VERSION ""

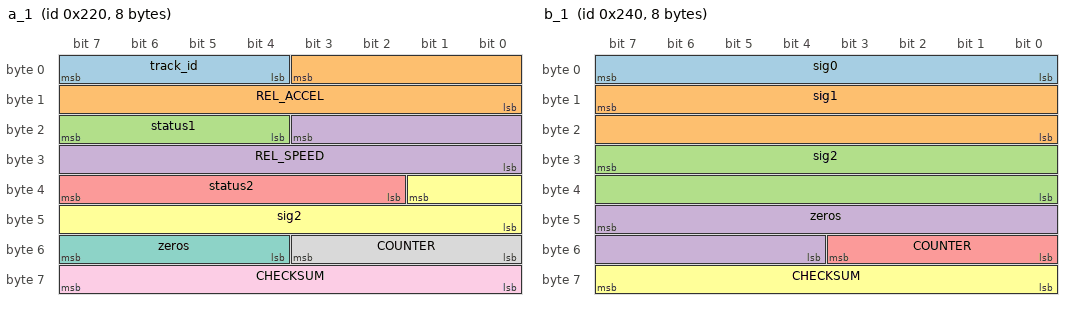
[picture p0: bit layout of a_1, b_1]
BO_ 544 a_1: 8 XXX
 SG_ track_id : 7|4@0+ (1,0) [0|15] "" XXX
 SG_ REL_ACCEL : 3|12@0+ (1,0) [0|31] "" XXX
 SG_ status1 : 23|4@0+ (1,0) [0|15] "" XXX
 SG_ REL_SPEED : 19|12@0+ (1,0) [0|65535] "" XXX
 SG_ status2 : 39|6@0+ (1,0) [0|15] "" XXX
 SG_ sig2 : 33|10@0+ (1,0) [0|255] "" XXX
 SG_ zeros : 55|4@0+ (1,0) [0|15] "" XXX
 SG_ COUNTER : 51|4@0+ (1,0) [0|15] "" XXX
 SG_ CHECKSUM : 63|8@0+ (1,0) [0|255] "" XXX

BO_ 576 b_1: 8 XXX
 SG_ sig0 : 7|8@0+ (1,0) [0|255] "" XXX
 SG_ sig1 : 15|16@0+ (1,0) [0|65535] "" XXX
 SG_ sig2 : 31|16@0+ (1,0) [0|255] "" XXX
 SG_ zeros : 47|12@0+ (1,0) [0|255] "" XXX
 SG_ COUNTER : 51|4@0+ (1,0) [0|15] "" XXX
 SG_ CHECKSUM : 63|8@0+ (1,0) [0|255] "" XXX

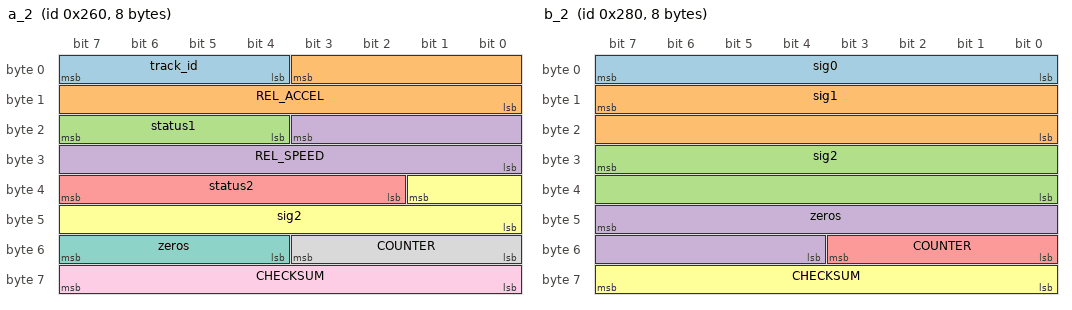
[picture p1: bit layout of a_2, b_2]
BO_ 608 a_2: 8 XXX
 SG_ track_id : 7|4@0+ (1,0) [0|15] "" XXX
 SG_ REL_ACCEL : 3|12@0+ (1,0) [0|31] "" XXX
 SG_ status1 : 23|4@0+ (1,0) [0|15] "" XXX
 SG_ REL_SPEED : 19|12@0+ (1,0) [0|65535] "" XXX
 SG_ status2 : 39|6@0+ (1,0) [0|15] "" XXX
 SG_ sig2 : 33|10@0+ (1,0) [0|255] "" XXX
 SG_ zeros : 55|4@0+ (1,0) [0|15] "" XXX
 SG_ COUNTER : 51|4@0+ (1,0) [0|15] "" XXX
 SG_ CHECKSUM : 63|8@0+ (1,0) [0|255] "" XXX

BO_ 640 b_2: 8 XXX
 SG_ sig0 : 7|8@0+ (1,0) [0|255] "" XXX
 SG_ sig1 : 15|16@0+ (1,0) [0|65535] "" XXX
 SG_ sig2 : 31|16@0+ (1,0) [0|255] "" XXX
 SG_ zeros : 47|12@0+ (1,0) [0|255] "" XXX
 SG_ COUNTER : 51|4@0+ (1,0) [0|15] "" XXX
 SG_ CHECKSUM : 63|8@0+ (1,0) [0|255] "" XXX

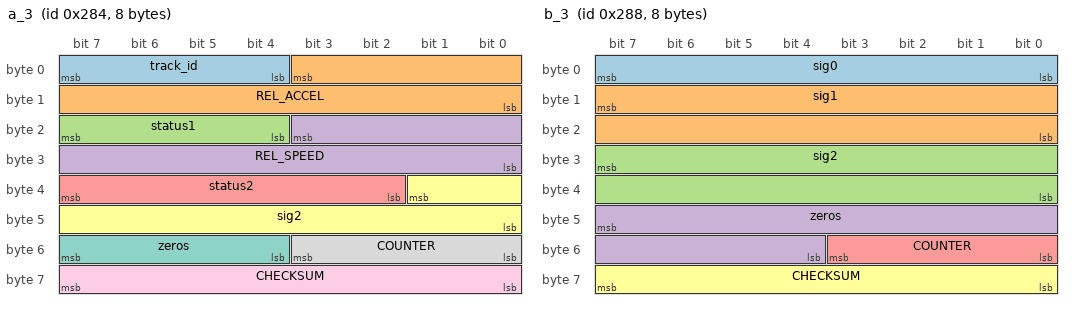
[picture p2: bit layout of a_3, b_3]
BO_ 644 a_3: 8 XXX
 SG_ track_id : 7|4@0+ (1,0) [0|15] "" XXX
 SG_ REL_ACCEL : 3|12@0+ (1,0) [0|31] "" XXX
 SG_ status1 : 23|4@0+ (1,0) [0|15] "" XXX
 SG_ REL_SPEED : 19|12@0+ (1,0) [0|65535] "" XXX
 SG_ status2 : 39|6@0+ (1,0) [0|15] "" XXX
 SG_ sig2 : 33|10@0+ (1,0) [0|255] "" XXX
 SG_ zeros : 55|4@0+ (1,0) [0|15] "" XXX
 SG_ COUNTER : 51|4@0+ (1,0) [0|15] "" XXX
 SG_ CHECKSUM : 63|8@0+ (1,0) [0|255] "" XXX

BO_ 648 b_3: 8 XXX
 SG_ sig0 : 7|8@0+ (1,0) [0|255] "" XXX
 SG_ sig1 : 15|16@0+ (1,0) [0|65535] "" XXX
 SG_ sig2 : 31|16@0+ (1,0) [0|255] "" XXX
 SG_ zeros : 47|12@0+ (1,0) [0|255] "" XXX
 SG_ COUNTER : 51|4@0+ (1,0) [0|15] "" XXX
 SG_ CHECKSUM : 63|8@0+ (1,0) [0|255] "" XXX

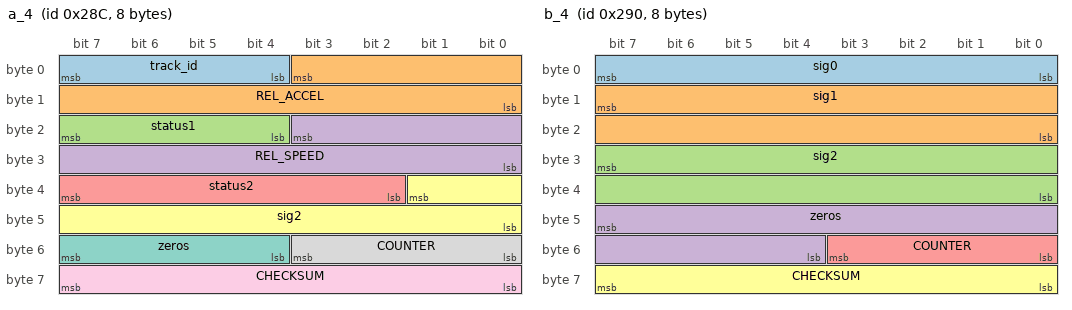
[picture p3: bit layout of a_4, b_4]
BO_ 652 a_4: 8 XXX
 SG_ track_id : 7|4@0+ (1,0) [0|15] "" XXX
 SG_ REL_ACCEL : 3|12@0+ (1,0) [0|31] "" XXX
 SG_ status1 : 23|4@0+ (1,0) [0|15] "" XXX
 SG_ REL_SPEED : 19|12@0+ (1,0) [0|65535] "" XXX
 SG_ status2 : 39|6@0+ (1,0) [0|15] "" XXX
 SG_ sig2 : 33|10@0+ (1,0) [0|255] "" XXX
 SG_ zeros : 55|4@0+ (1,0) [0|15] "" XXX
 SG_ COUNTER : 51|4@0+ (1,0) [0|15] "" XXX
 SG_ CHECKSUM : 63|8@0+ (1,0) [0|255] "" XXX

BO_ 656 b_4: 8 XXX
 SG_ sig0 : 7|8@0+ (1,0) [0|255] "" XXX
 SG_ sig1 : 15|16@0+ (1,0) [0|65535] "" XXX
 SG_ sig2 : 31|16@0+ (1,0) [0|255] "" XXX
 SG_ zeros : 47|12@0+ (1,0) [0|255] "" XXX
 SG_ COUNTER : 51|4@0+ (1,0) [0|15] "" XXX
 SG_ CHECKSUM : 63|8@0+ (1,0) [0|255] "" XXX

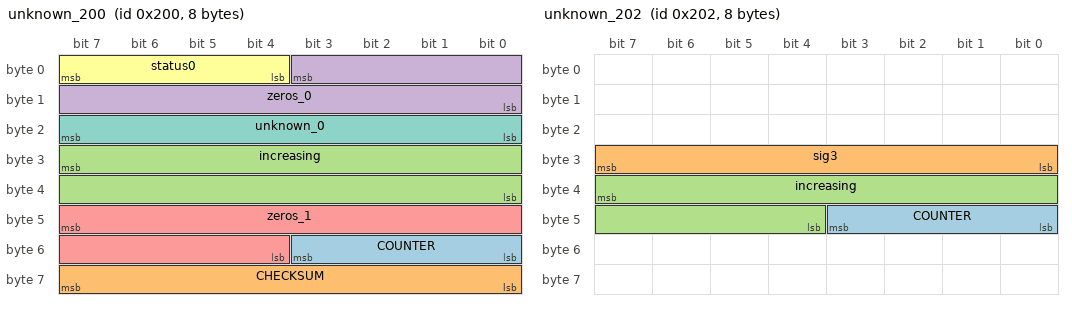
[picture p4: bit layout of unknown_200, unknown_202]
BO_ 512 unknown_200: 8 XXX
 SG_ COUNTER : 51|4@0+ (1,0) [0|15] "" XXX
 SG_ CHECKSUM : 63|8@0+ (1,0) [0|255] "" XXX
 SG_ increasing : 31|16@0+ (1,0) [0|255] "" XXX
 SG_ zeros_0 : 3|12@0+ (1,0) [0|63] "" XXX
 SG_ zeros_1 : 47|12@0+ (1,0) [0|63] "" XXX
 SG_ status0 : 7|4@0+ (1,0) [0|15] "" XXX
 SG_ unknown_0 : 23|8@0+ (1,0) [0|255] "" XXX

BO_ 514 unknown_202: 8 XXX
 SG_ COUNTER : 43|4@0+ (1,0) [0|15] "" XXX
 SG_ sig3 : 31|8@0+ (1,0) [0|65535] "" XXX
 SG_ increasing : 39|12@0+ (1,0) [0|15] "" XXX

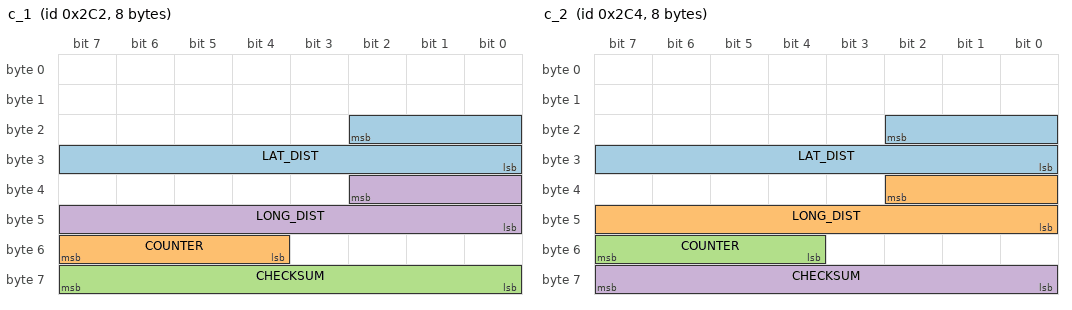
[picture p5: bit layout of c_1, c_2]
BO_ 706 c_1: 8 XXX
 SG_ LAT_DIST : 18|11@0+ (0.005,-1000) [0|2047] "m" XXX
 SG_ COUNTER : 55|4@0+ (1,0) [0|15] "" XXX
 SG_ CHECKSUM : 63|8@0+ (1,0) [0|255] "" XXX
 SG_ LONG_DIST : 34|11@0+ (0.073,0) [0|255] "m" XXX

BO_ 708 c_2: 8 XXX
 SG_ LAT_DIST : 18|11@0+ (0.005,-1000) [0|2047] "m" XXX
 SG_ LONG_DIST : 34|11@0+ (0.073,0) [0|255] "m" XXX
 SG_ COUNTER : 55|4@0+ (1,0) [0|15] "" XXX
 SG_ CHECKSUM : 63|8@0+ (1,0) [0|255] "" XXX

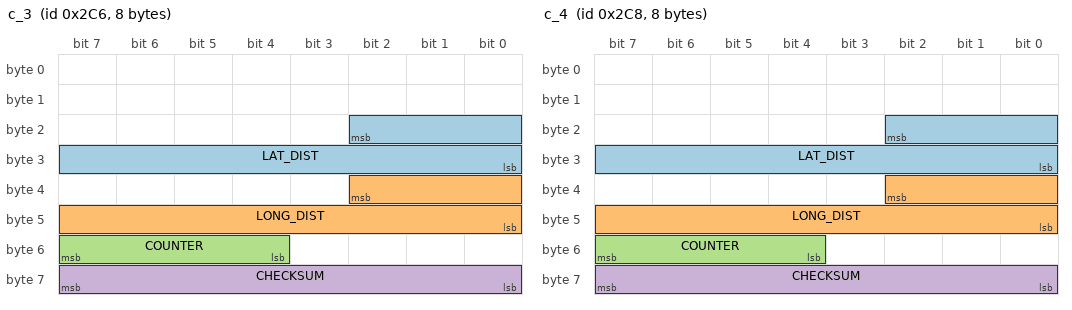
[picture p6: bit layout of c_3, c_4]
BO_ 710 c_3: 8 XXX
 SG_ LAT_DIST : 18|11@0+ (0.005,-1000) [0|2047] "m" XXX
 SG_ LONG_DIST : 34|11@0+ (0.073,0) [0|255] "m" XXX
 SG_ COUNTER : 55|4@0+ (1,0) [0|15] "" XXX
 SG_ CHECKSUM : 63|8@0+ (1,0) [0|255] "" XXX

BO_ 712 c_4: 8 XXX
 SG_ LAT_DIST : 18|11@0+ (0.005,-1000) [0|2047] "m" XXX
 SG_ LONG_DIST : 34|11@0+ (0.073,0) [0|255] "m" XXX
 SG_ COUNTER : 55|4@0+ (1,0) [0|15] "" XXX
 SG_ CHECKSUM : 63|8@0+ (1,0) [0|255] "" XXX

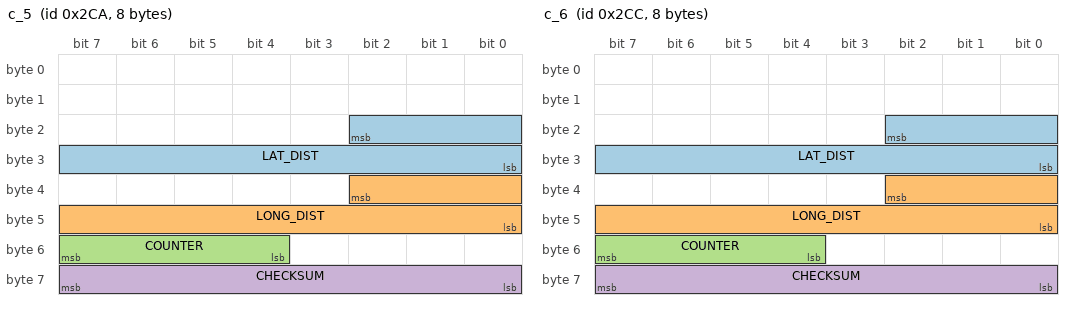
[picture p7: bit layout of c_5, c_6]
BO_ 714 c_5: 8 XXX
 SG_ LAT_DIST : 18|11@0+ (0.005,-1000) [0|2047] "m" XXX
 SG_ LONG_DIST : 34|11@0+ (0.073,0) [0|255] "m" XXX
 SG_ COUNTER : 55|4@0+ (1,0) [0|15] "" XXX
 SG_ CHECKSUM : 63|8@0+ (1,0) [0|255] "" XXX

BO_ 716 c_6: 8 XXX
 SG_ LAT_DIST : 18|11@0+ (0.005,-1000) [0|2047] "m" XXX
 SG_ LONG_DIST : 34|11@0+ (0.073,0) [0|255] "m" XXX
 SG_ COUNTER : 55|4@0+ (1,0) [0|15] "" XXX
 SG_ CHECKSUM : 63|8@0+ (1,0) [0|255] "" XXX

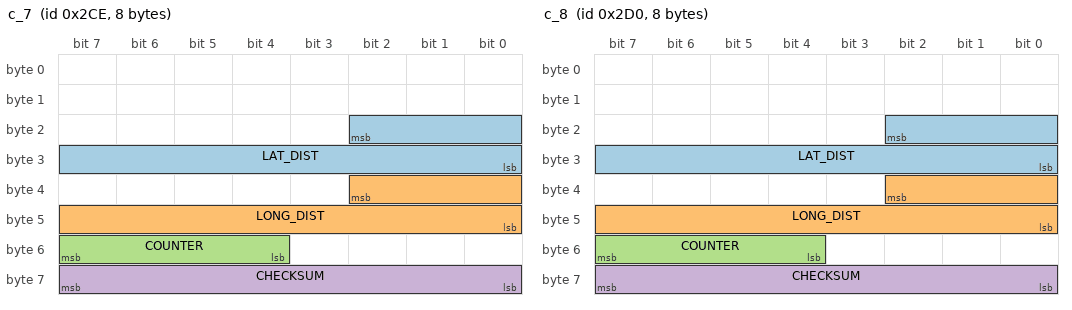
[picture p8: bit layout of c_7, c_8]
BO_ 718 c_7: 8 XXX
 SG_ LAT_DIST : 18|11@0+ (0.005,-1000) [0|2047] "m" XXX
 SG_ LONG_DIST : 34|11@0+ (0.073,0) [0|255] "m" XXX
 SG_ COUNTER : 55|4@0+ (1,0) [0|15] "" XXX
 SG_ CHECKSUM : 63|8@0+ (1,0) [0|255] "" XXX

BO_ 720 c_8: 8 XXX
 SG_ LAT_DIST : 18|11@0+ (0.005,-1000) [0|2047] "m" XXX
 SG_ LONG_DIST : 34|11@0+ (0.073,0) [0|255] "m" XXX
 SG_ COUNTER : 55|4@0+ (1,0) [0|15] "" XXX
 SG_ CHECKSUM : 63|8@0+ (1,0) [0|255] "" XXX

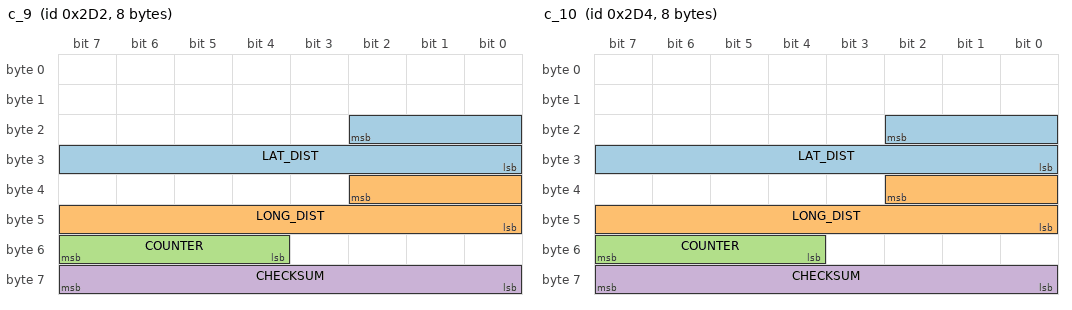
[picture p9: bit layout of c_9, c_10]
BO_ 722 c_9: 8 XXX
 SG_ LAT_DIST : 18|11@0+ (0.005,-1000) [0|2047] "m" XXX
 SG_ LONG_DIST : 34|11@0+ (0.073,0) [0|255] "m" XXX
 SG_ COUNTER : 55|4@0+ (1,0) [0|15] "" XXX
 SG_ CHECKSUM : 63|8@0+ (1,0) [0|255] "" XXX

BO_ 724 c_10: 8 XXX
 SG_ LAT_DIST : 18|11@0+ (0.005,-1000) [0|2047] "m" XXX
 SG_ LONG_DIST : 34|11@0+ (0.073,0) [0|255] "m" XXX
 SG_ COUNTER : 55|4@0+ (1,0) [0|15] "" XXX
 SG_ CHECKSUM : 63|8@0+ (1,0) [0|255] "" XXX

BO_ 674 d_1: 8 XXX
 SG_ REL_SPEED : 17|10@0+ (0.2857,-146.278) [0|1023] "m/s" XXX

BO_ 676 d_2: 8 XXX
 SG_ REL_SPEED : 17|10@0+ (0.2857,-146.278) [0|1023] "m/s" XXX

BO_ 678 d_3: 8 XXX
 SG_ REL_SPEED : 17|10@0+ (0.2857,-146.278) [0|1023] "m/s" XXX

BO_ 680 d_4: 8 XXX
 SG_ REL_SPEED : 17|10@0+ (0.2857,-146.278) [0|1023] "m/s" XXX

BO_ 682 d_5: 8 XXX
 SG_ REL_SPEED : 17|10@0+ (0.2857,-146.278) [0|1023] "m/s" XXX

BO_ 684 d_6: 8 XXX
 SG_ REL_SPEED : 17|10@0+ (0.2857,-146.278) [0|1023] "m/s" XXX

BO_ 686 d_7: 8 XXX
 SG_ REL_SPEED : 17|10@0+ (0.2857,-146.278) [0|1023] "m/s" XXX

BO_ 688 d_8: 8 XXX
 SG_ REL_SPEED : 17|10@0+ (0.2857,-146.278) [0|1023] "m/s" XXX

BO_ 690 d_9: 8 XXX
 SG_ REL_SPEED : 17|10@0+ (0.2857,-146.278) [0|1023] "m/s" XXX

BO_ 692 d_10: 8 XXX
 SG_ REL_SPEED : 17|10@0+ (0.2857,-146.278) [0|1023] "m/s" XXX

BO_ 672 NEW_MSG_5: 8 XXX
 SG_ NEW_SIGNAL_1 : 9|10@0+ (1,0) [0|1023] "" XXX
 SG_ NEW_SIGNAL_2 : 45|10@0+ (1,0) [0|1023] "" XXX

BU_: MRR
CM_ "AUTOGENERATED FILE, DO NOT EDIT";

CM_ "Imported file _honda_common.dbc starts here";
CM_ SG_ 304 "Seems to be platform-agnostic";
CM_ SG_ 316 "Should exist on Nidec";
CM_ SG_ 420 BRAKE_HOLD_RELATED "On when Brake Hold engaged";
CM_ SG_ 490 LONG_ACCEL "wheel speed derivative, noisy and zero snapping";
CM_ SG_ 773 PASS_AIRBAG_ON "Might just be indicator light";
CM_ SG_ 773 PASS_AIRBAG_OFF "Might just be indicator light";
CM_ SG_ 780 CRUISE_SPEED "255 = no speed";
CM_ SG_ 780 PCM_SPEED "Used by Nidec";
CM_ SG_ 780 PCM_GAS "Used by Nidec";
CM_ SG_ 804 CRUISE_SPEED_PCM "255 = no speed";

CM_ "Imported file _bosch_2018.dbc starts here";
CM_ SG_ 450 EPB_STATE "3: On, 2: Disengaging, 1: Engaging, 0: Off";
CM_ SG_ 576 LINE_DISTANCE_VISIBLE "Length of line visible, undecoded";
CM_ SG_ 577 LINE_FAR_EDGE_POSITION "Appears to be a measure of line thickness, indicates location of the portion of the line furthest from the car, undecoded";
CM_ SG_ 577 LINE_PARAMETER "Unclear if this is low quality line curvature rate or if this is something else, but it is correlated with line curvature, undecoded";
CM_ SG_ 577 LINE_DASHED "1 = line is dashed";
CM_ SG_ 577 LINE_SOLID "1 = line is solid";

CM_ "Imported file _bosch_adas_2018.dbc starts here";
CM_ SG_ 479 CONTROL_ON "Set to 5 when car is being controlled";
CM_ SG_ 479 AEB_STATUS "set for the duration of AEB event";
CM_ SG_ 479 AEB_BRAKING "set when braking is commanded during AEB event";
CM_ SG_ 479 AEB_PREPARE "set 1s before AEB";
CM_ SG_ 829 BEEP "beeps are pleasant, chimes are for warnngs etc...";

CM_ "Imported file _steering_sensors_a.dbc starts here";
CM_ "honda_crv_ex_2017_can.dbc starts here";

CM_ SG_ 479 RELATED_TO_GAS "bits 7, 3, and 1 set to 1 when gas not applied";
CM_ SG_ 479 GAS_BRAKE "Signed value, negative when braking and positive when applying gas";
